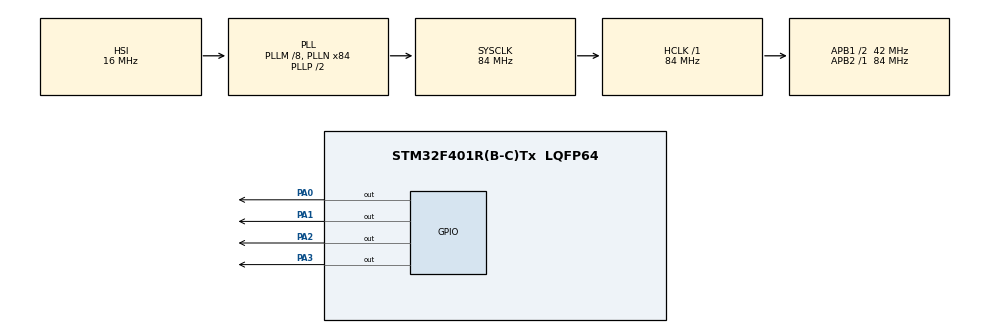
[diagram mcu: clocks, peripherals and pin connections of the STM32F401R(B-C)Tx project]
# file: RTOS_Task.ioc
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FREERTOS.Tasks01=defaultTask,0,128,StartDefaultTask,Default,NULL,Dynamic,NULL,NULL;Toggle_Led,2,128,StartTask02,Default,NULL,Dynamic,NULL,NULL
Mcu.Family=STM32F4
Mcu.Name=STM32F401R(B-C)Tx
Mcu.Package=LQFP64
NVIC.PriorityGroup=NVIC_PRIORITYGROUP_4
PA0-WKUP.Signal=GPIO_Output
PA1.Signal=GPIO_Output
PA2.Signal=GPIO_Output
PA3.Signal=GPIO_Output
ProjectManager.HeapSize=0x200
ProjectManager.StackSize=0x400
ProjectManager.TargetToolchain=STM32CubeIDE
RCC.48MHZClocksFreq_Value=42000000
RCC.AHBFreq_Value=84000000
RCC.APB1CLKDivider=RCC_HCLK_DIV2
RCC.APB1Freq_Value=42000000
RCC.APB1TimFreq_Value=84000000
RCC.APB2Freq_Value=84000000
RCC.APB2TimFreq_Value=84000000
RCC.CortexFreq_Value=84000000
RCC.HCLKFreq_Value=84000000
RCC.HSE_VALUE=25000000
RCC.HSI_VALUE=16000000
RCC.LSE_VALUE=32768
RCC.PLLM=8
RCC.PLLN=84
RCC.SYSCLKFreq_VALUE=84000000
RCC.SYSCLKSource=RCC_SYSCLKSOURCE_PLLCLK
RCC.VCOOutputFreq_Value=168000000
VP_FREERTOS_VS_CMSIS_V1.Mode=CMSIS_V1
board=custom

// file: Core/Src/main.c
/* USER CODE BEGIN Header */
/**
  ******************************************************************************
  * @file           : main.c
  * @brief          : Main program body
  ******************************************************************************
  * @attention
  *
  * Copyright (c) 2025 STMicroelectronics.
  * All rights reserved.
  *
  * This software is licensed under terms that can be found in the LICENSE file
  * in the root directory of this software component.
  * If no LICENSE file comes with this software, it is provided AS-IS.
  *
  ******************************************************************************
  */
/* USER CODE END Header */
#include "main.h"
#include "cmsis_os.h"
#include "gpio.h"

void SystemClock_Config(void);
void MX_FREERTOS_Init(void);

int main(void)
{

  /* MCU Configuration--------------------------------------------------------*/

  /* Reset of all peripherals, Initializes the Flash interface and the Systick. */
  HAL_Init();

  /* Configure the system clock */
  SystemClock_Config();

  /* Initialize all configured peripherals */
  MX_GPIO_Init();

  /* Call init function for freertos objects (in cmsis_os2.c) */
  MX_FREERTOS_Init();

  /* Start scheduler */
  osKernelStart();

  /* We should never get here as control is now taken by the scheduler */

  /* Infinite loop */
  while (1)
  {

  }
}

void SystemClock_Config(void)
{
  RCC_OscInitTypeDef RCC_OscInitStruct = {0};
  RCC_ClkInitTypeDef RCC_ClkInitStruct = {0};

  /** Configure the main internal regulator output voltage
  */
  __HAL_RCC_PWR_CLK_ENABLE();
  __HAL_PWR_VOLTAGESCALING_CONFIG(PWR_REGULATOR_VOLTAGE_SCALE2);

  /** Initializes the RCC Oscillators according to the specified parameters
  * in the RCC_OscInitTypeDef structure.
  */
  RCC_OscInitStruct.OscillatorType = RCC_OSCILLATORTYPE_HSI;
  RCC_OscInitStruct.HSIState = RCC_HSI_ON;
  RCC_OscInitStruct.HSICalibrationValue = RCC_HSICALIBRATION_DEFAULT;
  RCC_OscInitStruct.PLL.PLLState = RCC_PLL_ON;
  RCC_OscInitStruct.PLL.PLLSource = RCC_PLLSOURCE_HSI;
  RCC_OscInitStruct.PLL.PLLM = 8;
  RCC_OscInitStruct.PLL.PLLN = 84;
  RCC_OscInitStruct.PLL.PLLP = RCC_PLLP_DIV2;
  RCC_OscInitStruct.PLL.PLLQ = 4;
  if (HAL_RCC_OscConfig(&RCC_OscInitStruct) != HAL_OK)
  {
    Error_Handler();
  }

  /** Initializes the CPU, AHB and APB buses clocks
  */
  RCC_ClkInitStruct.ClockType = RCC_CLOCKTYPE_HCLK|RCC_CLOCKTYPE_SYSCLK
                              |RCC_CLOCKTYPE_PCLK1|RCC_CLOCKTYPE_PCLK2;
  RCC_ClkInitStruct.SYSCLKSource = RCC_SYSCLKSOURCE_PLLCLK;
  RCC_ClkInitStruct.AHBCLKDivider = RCC_SYSCLK_DIV1;
  RCC_ClkInitStruct.APB1CLKDivider = RCC_HCLK_DIV2;
  RCC_ClkInitStruct.APB2CLKDivider = RCC_HCLK_DIV1;

  if (HAL_RCC_ClockConfig(&RCC_ClkInitStruct, FLASH_LATENCY_2) != HAL_OK)
  {
    Error_Handler();
  }
}

void Error_Handler(void)
{
  __disable_irq();
  while (1)
  {
  }
}

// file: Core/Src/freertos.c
/* USER CODE BEGIN Header */
/**
  ******************************************************************************
  * File Name          : freertos.c
  * Description        : Code for freertos applications
  ******************************************************************************
  * @attention
  *
  * Copyright (c) 2025 STMicroelectronics.
  * All rights reserved.
  *
  * This software is licensed under terms that can be found in the LICENSE file
  * in the root directory of this software component.
  * If no LICENSE file comes with this software, it is provided AS-IS.
  *
  ******************************************************************************
  */
/* USER CODE END Header */

#include "FreeRTOS.h"
#include "task.h"
#include "main.h"
#include "cmsis_os.h"

osThreadId defaultTaskHandle;
osThreadId Toggle_LedHandle;

void StartDefaultTask(void const * argument);
void StartTask02(void const * argument);

void MX_FREERTOS_Init(void); /* (MISRA C 2004 rule 8.1) */

/* GetIdleTaskMemory prototype (linked to static allocation support) */
void vApplicationGetIdleTaskMemory( StaticTask_t **ppxIdleTaskTCBBuffer, StackType_t **ppxIdleTaskStackBuffer, uint32_t *pulIdleTaskStackSize );

/* USER CODE BEGIN GET_IDLE_TASK_MEMORY */
static StaticTask_t xIdleTaskTCBBuffer;
static StackType_t xIdleStack[configMINIMAL_STACK_SIZE];

void vApplicationGetIdleTaskMemory( StaticTask_t **ppxIdleTaskTCBBuffer, StackType_t **ppxIdleTaskStackBuffer, uint32_t *pulIdleTaskStackSize )
{
  *ppxIdleTaskTCBBuffer = &xIdleTaskTCBBuffer;
  *ppxIdleTaskStackBuffer = &xIdleStack[0];
  *pulIdleTaskStackSize = configMINIMAL_STACK_SIZE;
  /* place for user code */
}
/* USER CODE END GET_IDLE_TASK_MEMORY */

void MX_FREERTOS_Init(void) {

  /* Create the thread(s) */
  /* definition and creation of defaultTask */
  osThreadDef(defaultTask, StartDefaultTask, osPriorityNormal, 0, 128);
  defaultTaskHandle = osThreadCreate(osThread(defaultTask), NULL);

  /* definition and creation of Toggle_Led */
  osThreadDef(Toggle_Led, StartTask02, osPriorityHigh, 0, 128);
  Toggle_LedHandle = osThreadCreate(osThread(Toggle_Led), NULL);

}

void StartDefaultTask(void const * argument)
{
  for(;;)
  {
    osDelay(1);
  }
}

void StartTask02(void const * argument)
{
  /* USER CODE BEGIN StartTask02 */
  /* Infinite loop */
  for(;;)
  {
	  HAL_GPIO_TogglePin(GPIOA, GPIO_PIN_0);
	  vTaskDelay(500 / portTICK_PERIOD_MS);
  }
  /* USER CODE END StartTask02 */
}
